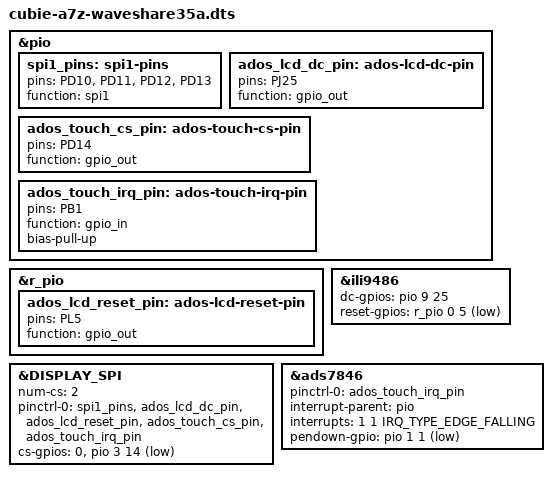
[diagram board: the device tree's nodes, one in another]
// SPDX-License-Identifier: GPL-2.0-or-later
/*
 * Device-tree overlay: 480x320 SPI LCD (ILI9486 + ADS7846) on the
 * 40-pin expansion header of the Radxa Cubie A7Z (Allwinner A733,
 * sun55iw3p1).
 *
 * Wiring (40-pin header, physical pin -> SoC pad):
 *   19  PD12  SPI1 MOSI
 *   21  PD13  SPI1 MISO
 *   23  PD11  SPI1 CLK
 *   24  PD10  SPI1 CS0   (LCD chip-select, hardware-managed)
 *   26  PD14  GPIO       (touch CS1, driven via cs-gpios)
 *   18  PJ25  GPIO out   (LCD data/command select)
 *   22  PL5   GPIO out   (LCD reset, on the AO/RTC pinctrl block)
 *   11  PB1   GPIO in    (touch pendown IRQ)
 *
 * Chip-level invariants (compatible, reg, spi-max-frequency, plate
 * resistance, pressure-max, swap-xy, invert-y, modern
 * touchscreen-max-pressure) live in upstream/waveshare35-lcd.dtsi.
 * This file overrides only SoC-specific bits: pinctrl groups, GPIO
 * bank/pin references, SPI controller routing.
 *
 * Bank-index assumption: Allwinner ``pio`` numbers banks A..J as 0..9
 * and the AO ``r_pio`` numbers PL=0, PM=1. Verify against the in-tree
 * sun55iw3p1 DTS on the first bench cycle and adjust if the running
 * kernel uses a different convention before tagging this overlay
 * stable.
 */

#define DISPLAY_SPI spi1
#include "upstream/waveshare35-lcd.dtsi"

&pio {
    spi1_pins: spi1-pins {
        pins = "PD10", "PD11", "PD12", "PD13";
        function = "spi1";
    };

    ados_lcd_dc_pin: ados-lcd-dc-pin {
        pins = "PJ25";
        function = "gpio_out";
    };

    ados_touch_cs_pin: ados-touch-cs-pin {
        pins = "PD14";
        function = "gpio_out";
    };

    ados_touch_irq_pin: ados-touch-irq-pin {
        pins = "PB1";
        function = "gpio_in";
        bias-pull-up;
    };
};

&r_pio {
    ados_lcd_reset_pin: ados-lcd-reset-pin {
        pins = "PL5";
        function = "gpio_out";
    };
};

&DISPLAY_SPI {
    num-cs = <2>;
    pinctrl-names = "default";
    pinctrl-0 = <&spi1_pins>,
                <&ados_lcd_dc_pin>,
                <&ados_lcd_reset_pin>,
                <&ados_touch_cs_pin>,
                <&ados_touch_irq_pin>;

    /* CS0: hardware-managed for LCD on PD10
     * CS1: PD14, GPIO chip-select for touch (active-low) */
    cs-gpios = <0>, <&pio 3 14 GPIO_ACTIVE_LOW>;
};

&ili9486 {
    /* PJ25 - header pin 18 - &pio bank 9, active high */
    dc-gpios = <&pio 9 25 GPIO_ACTIVE_HIGH>;
    /* PL5 - header pin 22 - &r_pio bank 0, active low */
    reset-gpios = <&r_pio 0 5 GPIO_ACTIVE_LOW>;
};

&ads7846 {
    pinctrl-names = "default";
    pinctrl-0 = <&ados_touch_irq_pin>;
    /* PB1 - header pin 11 - &pio bank 1, falling-edge IRQ */
    interrupt-parent = <&pio>;
    interrupts = <1 1 IRQ_TYPE_EDGE_FALLING>;
    pendown-gpio = <&pio 1 1 GPIO_ACTIVE_LOW>;
};
